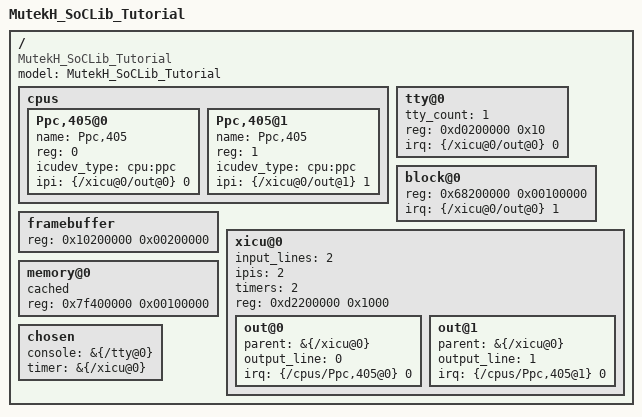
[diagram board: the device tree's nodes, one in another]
/dts-v1/;

/ {
	model = "MutekH_SoCLib_Tutorial";
	compatible = "MutekH_SoCLib_Tutorial";
	#address-cells = <1>;
	#size-cells = <1>;

	cpus {
		#address-cells = <1>;
		#size-cells = <0>;
		Ppc,405@0 {
			name = "Ppc,405";
			device_type = "cpu";
			reg = <0>;
			icudev_type = "cpu:ppc";
			ipi = <&{/xicu@0/out@0} 0>;
		};

		Ppc,405@1 {
			name = "Ppc,405";
			device_type = "cpu";
			reg = <1>;
			icudev_type = "cpu:ppc";
			ipi = <&{/xicu@0/out@1} 1>;
		};
	};

	tty@0 {
	    device_type = "soclib:tty";
		tty_count = <1>;
		reg = <0xd0200000 0x10>;
		irq = <&{/xicu@0/out@0} 0>;
	};

	block@0 {
	    device_type = "soclib:ramdisk";
		reg = <0x68200000 0x00100000>;
		irq = <&{/xicu@0/out@0} 1>;
	};

	framebuffer {
	    device_type = "soclib:framebuffer";
	        reg = <0x10200000 0x00200000>;
	};

	xicu@0 {
	    device_type = "soclib:xicu:root";
		input_lines = <2>;
		ipis = <2>;
		timers = <2>;
		reg = <0xd2200000 0x1000>;

	    	out@0 {
	    	    device_type = "soclib:xicu:filter";
	    	    parent = &{/xicu@0};
	    		output_line = <0>;
	    		irq = <&{/cpus/Ppc,405@0} 0>;
	    	};

		out@1 {
	    	    device_type = "soclib:xicu:filter";
	    	    parent = &{/xicu@0};
	    		output_line = <1>;
	    		irq = <&{/cpus/Ppc,405@1} 0>;
	    	};
	};

	memory@0 {
		device_type = "memory";
		cached;
		memreg: reg = <0x7f400000 0x00100000>;
	};

	chosen {
		console = &{/tty@0};
		timer = &{/xicu@0};
	};
};
